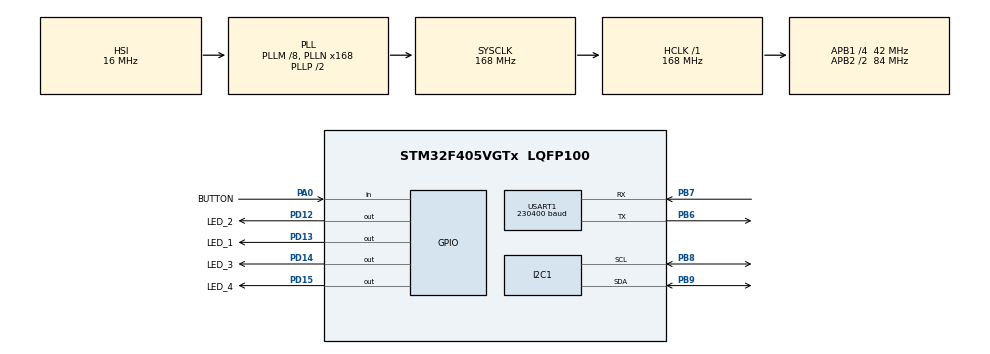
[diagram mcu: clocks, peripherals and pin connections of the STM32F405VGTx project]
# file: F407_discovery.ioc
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Dma.I2C1_RX.0.Direction=DMA_PERIPH_TO_MEMORY
Dma.I2C1_RX.0.FIFOMode=DMA_FIFOMODE_DISABLE
Dma.I2C1_RX.0.Instance=DMA1_Stream0
Dma.I2C1_RX.0.MemDataAlignment=DMA_MDATAALIGN_BYTE
Dma.I2C1_RX.0.MemInc=DMA_MINC_ENABLE
Dma.I2C1_RX.0.Mode=DMA_NORMAL
Dma.I2C1_RX.0.PeriphDataAlignment=DMA_PDATAALIGN_BYTE
Dma.I2C1_RX.0.PeriphInc=DMA_PINC_DISABLE
Dma.I2C1_RX.0.Priority=DMA_PRIORITY_LOW
Dma.I2C1_TX.1.Direction=DMA_MEMORY_TO_PERIPH
Dma.I2C1_TX.1.FIFOMode=DMA_FIFOMODE_DISABLE
Dma.I2C1_TX.1.Instance=DMA1_Stream6
Dma.I2C1_TX.1.MemDataAlignment=DMA_MDATAALIGN_BYTE
Dma.I2C1_TX.1.MemInc=DMA_MINC_ENABLE
Dma.I2C1_TX.1.Mode=DMA_NORMAL
Dma.I2C1_TX.1.PeriphDataAlignment=DMA_PDATAALIGN_BYTE
Dma.I2C1_TX.1.PeriphInc=DMA_PINC_DISABLE
Dma.I2C1_TX.1.Priority=DMA_PRIORITY_LOW
Dma.Request0=I2C1_RX
Dma.Request1=I2C1_TX
I2C1.I2C_Mode=I2C_Fast
Mcu.Family=STM32F4
Mcu.Name=STM32F405VGTx
Mcu.Package=LQFP100
NVIC.DMA1_Stream0_IRQn=true\:0\:0\:false\:false\:true\:false\:true
NVIC.DMA1_Stream6_IRQn=true\:0\:0\:false\:false\:true\:false\:true
NVIC.PriorityGroup=NVIC_PRIORITYGROUP_4
NVIC.TIM2_IRQn=true\:0\:0\:false\:false\:true\:true\:true
PA0-WKUP.GPIO_Label=BUTTON
PA0-WKUP.GPIO_PuPd=GPIO_NOPULL
PA0-WKUP.Signal=GPIO_Input
PA13.Mode=Trace_Asynchronous_SW
PA13.Signal=SYS_JTMS-SWDIO
PA14.Mode=Trace_Asynchronous_SW
PA14.Signal=SYS_JTCK-SWCLK
PB3.Mode=Trace_Asynchronous_SW
PB3.Signal=SYS_JTDO-SWO
PB6.Mode=Asynchronous
PB6.Signal=USART1_TX
PB7.Mode=Asynchronous
PB7.Signal=USART1_RX
PB8.Mode=I2C
PB8.Signal=I2C1_SCL
PB9.Mode=I2C
PB9.Signal=I2C1_SDA
PD12.GPIO_Label=LED_2
PD12.Signal=GPIO_Output
PD13.GPIO_Label=LED_1
PD13.Signal=GPIO_Output
PD14.GPIO_Label=LED_3
PD14.Signal=GPIO_Output
PD15.GPIO_Label=LED_4
PD15.Signal=GPIO_Output
ProjectManager.HeapSize=0x200
ProjectManager.StackSize=0x400
ProjectManager.TargetToolchain=STM32CubeIDE
RCC.48MHZClocksFreq_Value=84000000
RCC.AHBFreq_Value=168000000
RCC.APB1CLKDivider=RCC_HCLK_DIV4
RCC.APB1Freq_Value=42000000
RCC.APB1TimFreq_Value=84000000
RCC.APB2CLKDivider=RCC_HCLK_DIV2
RCC.APB2Freq_Value=84000000
RCC.APB2TimFreq_Value=168000000
RCC.CortexFreq_Value=168000000
RCC.HCLKFreq_Value=168000000
RCC.HSE_VALUE=25000000
RCC.HSI_VALUE=16000000
RCC.LSE_VALUE=32768
RCC.PLLM=8
RCC.PLLN=168
RCC.SYSCLKFreq_VALUE=168000000
RCC.SYSCLKSource=RCC_SYSCLKSOURCE_PLLCLK
RCC.VCOOutputFreq_Value=336000000
TIM2.AutoReloadPreload=TIM_AUTORELOAD_PRELOAD_ENABLE
TIM2.Period=99
TIM2.Prescaler=167
USART1.BaudRate=230400
USART1.VirtualMode=VM_ASYNC
VP_TIM2_VS_ClockSourceINT.Mode=Internal
board=custom

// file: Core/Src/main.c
/* USER CODE BEGIN Header */
/**
  ******************************************************************************
  * @file           : main.c
  * @brief          : Main program body
  ******************************************************************************
  * @attention
  *
  * <h2><center>&copy; Copyright (c) 2020 STMicroelectronics.
  * All rights reserved.</center></h2>
  *
  * This software component is licensed by ST under BSD 3-Clause license,
  * the "License"; You may not use this file except in compliance with the
  * License. You may obtain a copy of the License at:
  *                        opensource.org/licenses/BSD-3-Clause
  *
  ******************************************************************************
  */
/* USER CODE END Header */
#include "main.h"
#include "dma.h"
#include "i2c.h"
#include "tim.h"
#include "usart.h"
#include "gpio.h"

void SystemClock_Config(void);

int main(void)
{

  /* MCU Configuration--------------------------------------------------------*/

  /* Reset of all peripherals, Initializes the Flash interface and the Systick. */
  HAL_Init();

  /* USER CODE BEGIN Init */

  system_t sys ;

  /* USER CODE END Init */

  /* Configure the system clock */
  SystemClock_Config();

  /* Initialize all configured peripherals */
  MX_GPIO_Init();
  MX_DMA_Init();
  MX_I2C1_Init();
  MX_USART1_UART_Init();
  MX_TIM2_Init();
  /* USER CODE BEGIN 2 */

  SCHEDULER_init(&sys);
  EVENT_init(&sys, &htim2);

  LED_SEQUENCE_init(&sys.led, LED_1_GPIO_Port, LED_1_Pin, SEQUENCE_LED_1, 200, 12, 1);

  MPU_init(&sys.sensors.mpu, &hi2c1);
  GYRO_init(&sys.sensors.gyro, &sys.sensors.mpu);
  if(sys.sensors.gyro.state != SENSOR_IDDLE)
	  LED_SEQUENCE_set_sequence(&sys.led, SEQUENCE_LED_2);
  /* USER CODE END 2 */

  /* Infinite loop */
  /* USER CODE BEGIN WHILE */
  while (1)
  {

	  SCHEDULER_run();
    /* USER CODE END WHILE */

  }
}

void SystemClock_Config(void)
{
  RCC_OscInitTypeDef RCC_OscInitStruct = {0};
  RCC_ClkInitTypeDef RCC_ClkInitStruct = {0};

  /** Configure the main internal regulator output voltage
  */
  __HAL_RCC_PWR_CLK_ENABLE();
  __HAL_PWR_VOLTAGESCALING_CONFIG(PWR_REGULATOR_VOLTAGE_SCALE1);
  /** Initializes the RCC Oscillators according to the specified parameters
  * in the RCC_OscInitTypeDef structure.
  */
  RCC_OscInitStruct.OscillatorType = RCC_OSCILLATORTYPE_HSI;
  RCC_OscInitStruct.HSIState = RCC_HSI_ON;
  RCC_OscInitStruct.HSICalibrationValue = RCC_HSICALIBRATION_DEFAULT;
  RCC_OscInitStruct.PLL.PLLState = RCC_PLL_ON;
  RCC_OscInitStruct.PLL.PLLSource = RCC_PLLSOURCE_HSI;
  RCC_OscInitStruct.PLL.PLLM = 8;
  RCC_OscInitStruct.PLL.PLLN = 168;
  RCC_OscInitStruct.PLL.PLLP = RCC_PLLP_DIV2;
  RCC_OscInitStruct.PLL.PLLQ = 4;
  if (HAL_RCC_OscConfig(&RCC_OscInitStruct) != HAL_OK)
  {
    Error_Handler();
  }
  /** Initializes the CPU, AHB and APB buses clocks
  */
  RCC_ClkInitStruct.ClockType = RCC_CLOCKTYPE_HCLK|RCC_CLOCKTYPE_SYSCLK
                              |RCC_CLOCKTYPE_PCLK1|RCC_CLOCKTYPE_PCLK2;
  RCC_ClkInitStruct.SYSCLKSource = RCC_SYSCLKSOURCE_PLLCLK;
  RCC_ClkInitStruct.AHBCLKDivider = RCC_SYSCLK_DIV1;
  RCC_ClkInitStruct.APB1CLKDivider = RCC_HCLK_DIV4;
  RCC_ClkInitStruct.APB2CLKDivider = RCC_HCLK_DIV2;

  if (HAL_RCC_ClockConfig(&RCC_ClkInitStruct, FLASH_LATENCY_5) != HAL_OK)
  {
    Error_Handler();
  }
}

void Error_Handler(void)
{
}

/************************ (C) COPYRIGHT STMicroelectronics *****END OF FILE****/
